# MIMXRT1062 register map
Vendor: nxp.com; File version: 1.0
CPU: CM7 r0p1, little endian, MPU, FPU, VTOR, 4 interrupt priority bits
Registers are 32-bit, read-write, reset 0x0 unless marked. A register's access mark holds for its fields unless they carry their own. Offsets are from the block's base; [hi:lo] are bit positions; {n}, {i} and the like mark numbered series; 'fields as' and 'values as' point back to an identical list.

## IOMUXC_SNVS
Base 0x400A8000; register names take the prefix IOMUXC_SNVS_
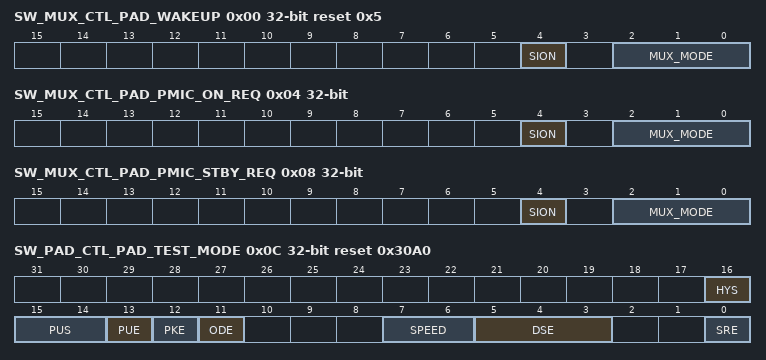
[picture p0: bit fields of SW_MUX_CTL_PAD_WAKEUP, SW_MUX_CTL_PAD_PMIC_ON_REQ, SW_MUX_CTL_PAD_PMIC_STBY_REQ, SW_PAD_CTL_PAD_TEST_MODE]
0x00 SW_MUX_CTL_PAD_WAKEUP reset 0x5 — SW_MUX_CTL_PAD_WAKEUP SW MUX Control Register
  [4] SION — Software Input On Field.
    0=DISABLED (Input Path is determined by functionality); 1=ENABLED (Force input path of pad WAKEUP)
  [2:0] MUX_MODE — MUX Mode Select Field.
    5=ALT5 (Select mux mode: ALT5 mux port: GPIO5_IO00 of instance: gpio5); 7=ALT7 (Select mux mode: ALT7 mux port: NMI_GLUE_NMI of instance: nmi_glue)
0x04 SW_MUX_CTL_PAD_PMIC_ON_REQ — SW_MUX_CTL_PAD_PMIC_ON_REQ SW MUX Control Register
  [4] SION — Software Input On Field.
    0=DISABLED (Input Path is determined by functionality); 1=ENABLED (Force input path of pad PMIC_ON_REQ)
  [2:0] MUX_MODE — MUX Mode Select Field.
    0=ALT0 (Select mux mode: ALT0 mux port: SNVS_LP_PMIC_ON_REQ of instance: snvs_lp); 5=ALT5 (Select mux mode: ALT5 mux port: GPIO5_IO01 of instance: gpio5)
0x08 SW_MUX_CTL_PAD_PMIC_STBY_REQ — SW_MUX_CTL_PAD_PMIC_STBY_REQ SW MUX Control Register
  [4] SION — Software Input On Field.
    0=DISABLED (Input Path is determined by functionality); 1=ENABLED (Force input path of pad PMIC_STBY_REQ)
  [2:0] MUX_MODE — MUX Mode Select Field.
    0=ALT0 (Select mux mode: ALT0 mux port: CCM_PMIC_VSTBY_REQ of instance: ccm); 5=ALT5 (Select mux mode: ALT5 mux port: GPIO5_IO02 of instance: gpio5)
0x0C SW_PAD_CTL_PAD_TEST_MODE reset 0x30A0 — SW_PAD_CTL_PAD_TEST_MODE SW PAD Control Register
  [16] HYS — Hyst. Enable Field
    0=HYS_0_Hysteresis_Disabled (Hysteresis Disabled); 1=HYS_1_Hysteresis_Enabled (Hysteresis Enabled)
  [15:14] PUS — Pull Up / Down Config. Field
    0=PUS_0_100K_Ohm_Pull_Down (100K Ohm Pull Down); 1=PUS_1_47K_Ohm_Pull_Up (47K Ohm Pull Up); 2=PUS_2_100K_Ohm_Pull_Up (100K Ohm Pull Up); 3=PUS_3_22K_Ohm_Pull_Up (22K Ohm Pull Up)
  [13] PUE — Pull / Keep Select Field
    0=PUE_0_Keeper (Keeper); 1=PUE_1_Pull (Pull)
  [12] PKE — Pull / Keep Enable Field
    0=PKE_0_Pull_Keeper_Disabled (Pull/Keeper Disabled); 1=PKE_1_Pull_Keeper_Enabled (Pull/Keeper Enabled)
  [11] ODE — Open Drain Enable Field
    0=ODE_0_Open_Drain_Disabled (Open Drain Disabled); 1=ODE_1_Open_Drain_Enabled (Open Drain Enabled)
  [7:6] SPEED ro
    2=SPEED (medium(100MHz))
  [5:3] DSE — Drive Strength Field
    0=DSE_0_output_driver_disabled_ (output driver disabled;); 1=DSE_1_R0_260_Ohm___3_3V__150_Ohm_1_8V__240_Ohm_for_DDR_ (R0(260 Ohm @ 3.3V, 150 Ohm@1.8V, 240 Ohm for DDR)); {v}=DSE_{v}_R0_{v} (R0/{v}) (v=2..7)
  [0] SRE — Slew Rate Field
    0=SRE_0_Slow_Slew_Rate (Slow Slew Rate); 1=SRE_1_Fast_Slew_Rate (Fast Slew Rate)
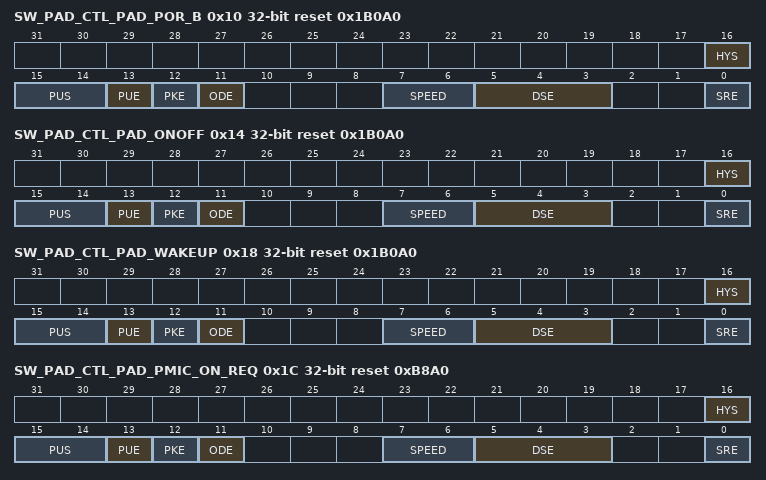
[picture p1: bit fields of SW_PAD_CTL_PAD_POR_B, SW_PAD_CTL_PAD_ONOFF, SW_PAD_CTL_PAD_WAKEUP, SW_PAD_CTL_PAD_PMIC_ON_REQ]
0x10 SW_PAD_CTL_PAD_POR_B reset 0x1B0A0 — SW_PAD_CTL_PAD_POR_B SW PAD Control Register
  fields as SW_PAD_CTL_PAD_TEST_MODE
0x14 SW_PAD_CTL_PAD_ONOFF reset 0x1B0A0 — SW_PAD_CTL_PAD_ONOFF SW PAD Control Register
  fields as SW_PAD_CTL_PAD_TEST_MODE
0x18 SW_PAD_CTL_PAD_WAKEUP reset 0x1B0A0 — SW_PAD_CTL_PAD_WAKEUP SW PAD Control Register
  fields as SW_PAD_CTL_PAD_TEST_MODE
0x1C SW_PAD_CTL_PAD_PMIC_ON_REQ reset 0xB8A0 — SW_PAD_CTL_PAD_PMIC_ON_REQ SW PAD Control Register
  fields as SW_PAD_CTL_PAD_TEST_MODE
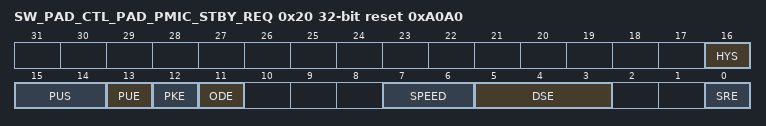
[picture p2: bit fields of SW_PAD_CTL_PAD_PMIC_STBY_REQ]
0x20 SW_PAD_CTL_PAD_PMIC_STBY_REQ reset 0xA0A0 — SW_PAD_CTL_PAD_PMIC_STBY_REQ SW PAD Control Register
  fields as SW_PAD_CTL_PAD_TEST_MODE

## FLEXRAM
Base 0x400B0000
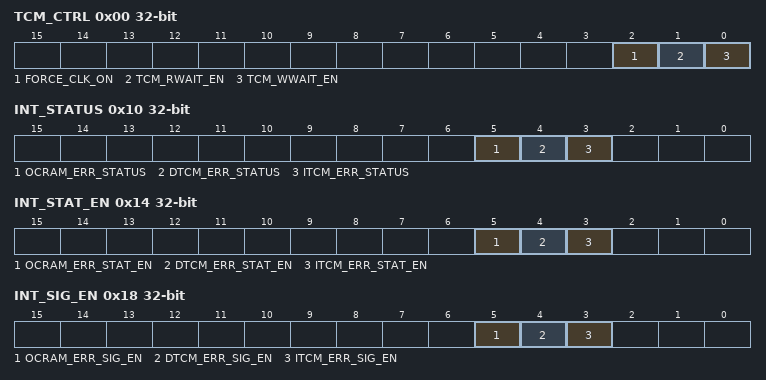
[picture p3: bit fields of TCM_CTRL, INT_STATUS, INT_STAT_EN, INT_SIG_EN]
0x00 TCM_CTRL — TCM CRTL Register
  [2] FORCE_CLK_ON — Force RAM Clock Always On
  [1] TCM_RWAIT_EN — TCM Read Wait Mode Enable
    0=TCM read fast mode: Read RAM accesses are expected to be finished in 1-cycle; 1=TCM read wait mode: Read RAM accesses are expected to be finished in 2-cycles
  [0] TCM_WWAIT_EN — TCM Write Wait Mode Enable
    0=TCM write fast mode: Write RAM accesses are expected to be finished in 1-cycle; 1=TCM write wait mode: Write RAM accesses are expected to be finished in 2-cycles
0x10 INT_STATUS — Interrupt Status Register
  [5] OCRAM_ERR_STATUS write-1-clears — OCRAM Access Error Status
    0=OCRAM access error does not happen; 1=OCRAM access error happens
  [4] DTCM_ERR_STATUS write-1-clears — DTCM Access Error Status
    0=DTCM access error does not happen; 1=DTCM access error happens
  [3] ITCM_ERR_STATUS write-1-clears — ITCM Access Error Status
    0=ITCM access error does not happen; 1=ITCM access error happens
0x14 INT_STAT_EN — Interrupt Status Enable Register
  [all] fields
    0=Masked; 1=Enabled
  [5] OCRAM_ERR_STAT_EN — OCRAM Access Error Status Enable
  [4] DTCM_ERR_STAT_EN — DTCM Access Error Status Enable
  [3] ITCM_ERR_STAT_EN — ITCM Access Error Status Enable
0x18 INT_SIG_EN — Interrupt Enable Register
  [all] fields
    0=Masked; 1=Enabled
  [5] OCRAM_ERR_SIG_EN — OCRAM Access Error Interrupt Enable
  [4] DTCM_ERR_SIG_EN — DTCM Access Error Interrupt Enable
  [3] ITCM_ERR_SIG_EN — ITCM Access Error Interrupt Enable

## Notices in the file
Copyright 2016-2019 NXP
All rights reserved.
SPDX-License-Identifier: BSD-3-Clause
